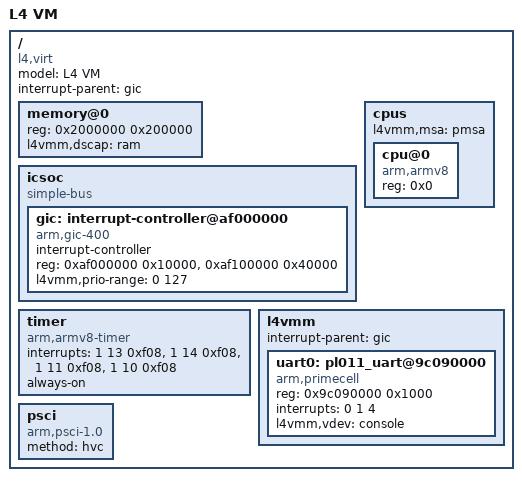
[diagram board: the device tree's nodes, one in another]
/dts-v1/;
/include/ "skeleton.dtsi"

/ {
    model = "L4 VM";
    compatible = "l4,virt", "linux,dummy-virt";

    interrupt-parent = <&gic>;

    memory@0 {
        device_type = "memory";
        reg = <0x2000000 0x200000>;
        l4vmm,dscap = "ram";
    };

    icsoc {
        compatible = "simple-bus";
        #address-cells = <1>;
        #size-cells = <1>;
        ranges;

        /* Uvmm will adapt the compatible string depending on the present gic
         * version. It expects reg entries that provide enough space for the
         * Cpu/Dist interface for gicv2 (at least 0x1000, 0x1000) or the
         * Dist/Redist interface for gicv3 (0x10000, 0x20000 * number of cpus).
         * The entries provided here support any gicv2 setup or a gicv3 setup
         * with one Cpu.
         */
        gic: interrupt-controller@af000000 {
            compatible = "arm,gic-400", "arm,cortex-a15-gic", "arm,cortex-a9-gic";
            #interrupt-cells = <3>;
            #address-cells = <0>;
            interrupt-controller;
            reg = <0xaf000000 0x10000>,
                  <0xaf100000 0x40000>;
            l4vmm,prio-range = <0 127>;
        };
    };

    timer {
      compatible = "arm,armv8-timer";
      interrupts = <1 13 0xf08>,
                   <1 14 0xf08>,
                   <1 11 0xf08>,
                   <1 10 0xf08>;
      always-on;
    };

    cpus {
      #address-cells = <1>;
      #size-cells = <0>;
      l4vmm,msa = "pmsa";

      cpu@0 {
        device_type = "cpu";
        compatible = "arm,armv8";
        reg = <0x0>;
      };
    };

    l4vmm {
        interrupt-parent = <&gic>;
        #address-cells = <1>;
        #size-cells = <1>;
        ranges;

        /*
         * Virtual PL011 UART at 0xf1100000
         */
        uart0: pl011_uart@9c090000 {
            compatible = "arm,primecell", "arm,pl011";
            reg = <0x9c090000 0x1000>;
            interrupts = <0 1 4>;
            l4vmm,vdev = "console";
        };
    };

    psci {
        compatible = "arm,psci-1.0";
        method = "hvc";
    };
};
